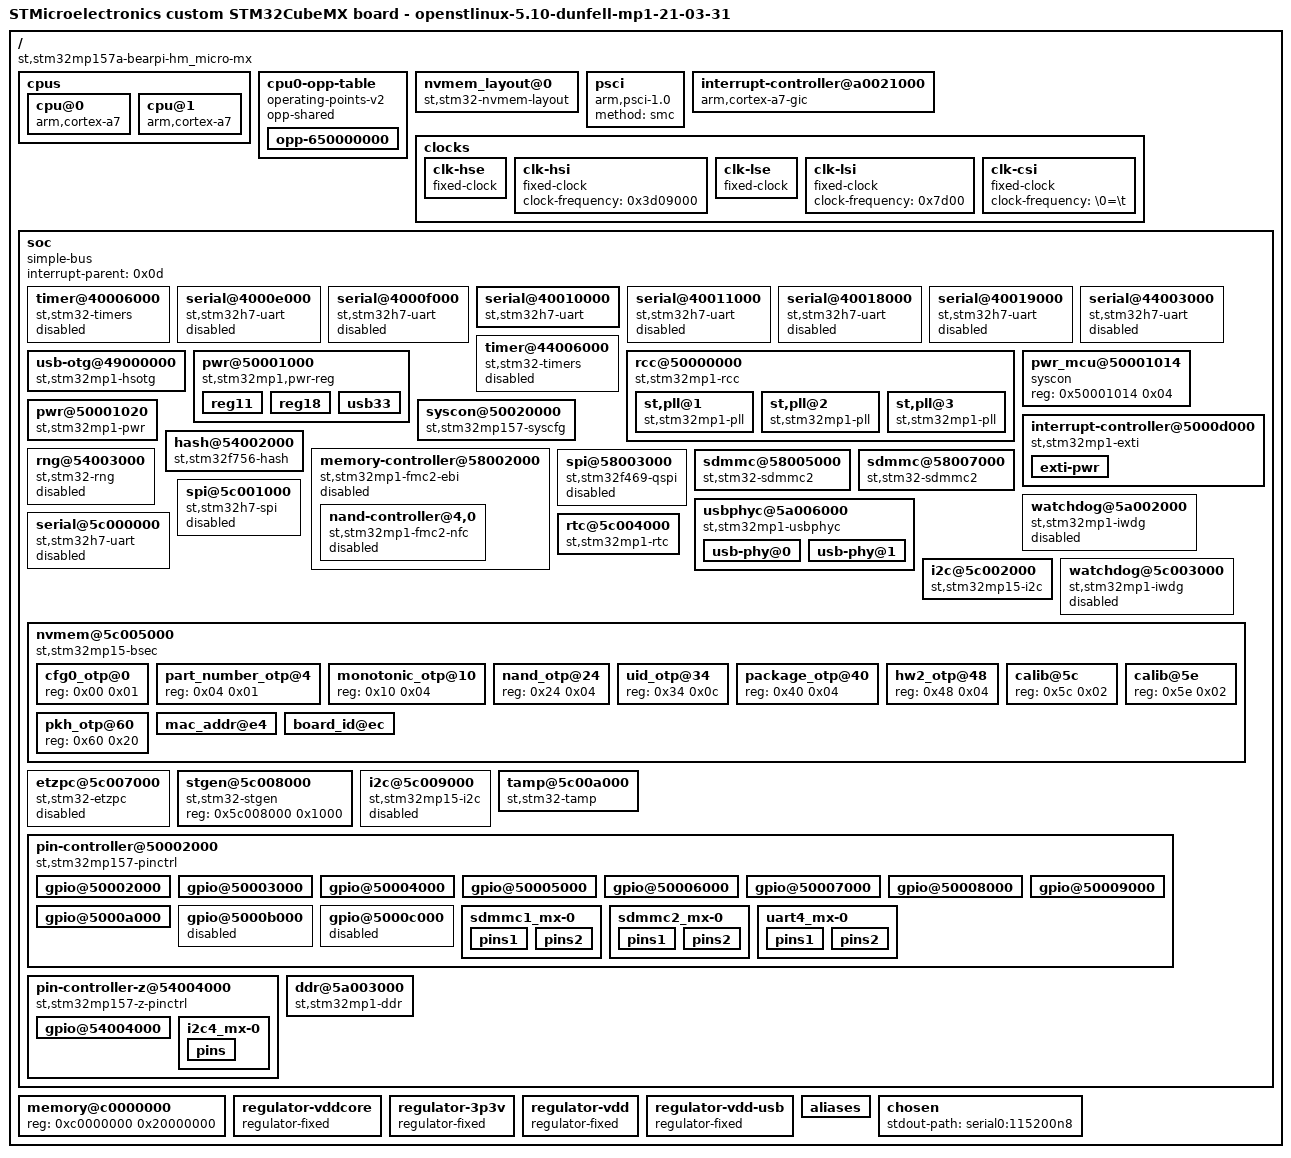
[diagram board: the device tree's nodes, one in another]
/dts-v1/;

/ {
	#address-cells = <0x01>;
	#size-cells = <0x01>;
	model = "STMicroelectronics custom STM32CubeMX board - openstlinux-5.10-dunfell-mp1-21-03-31";
	compatible = "st,stm32mp157a-bearpi-hm_micro-mx\0st,stm32mp157";

	cpus {
		#address-cells = <0x01>;
		#size-cells = <0x00>;

		cpu@0 {
			compatible = "arm,cortex-a7";
			device_type = "cpu";
			reg = <0x00>;
			clocks = <0x01 0xc2>;
			clock-names = "cpu";
			operating-points-v2 = <0x02>;
			nvmem-cells = <0x03>;
			nvmem-cell-names = "part_number";
			cpu-supply = <0x04>;
		};

		cpu@1 {
			compatible = "arm,cortex-a7";
			device_type = "cpu";
			reg = <0x01>;
			clocks = <0x01 0xc2>;
			clock-names = "cpu";
			operating-points-v2 = <0x02>;
			cpu-supply = <0x04>;
		};
	};

	cpu0-opp-table {
		compatible = "operating-points-v2";
		opp-shared;
		phandle = <0x02>;

		opp-650000000 {
			opp-hz = <0x00 0x26be3680>;
			opp-microvolt = <0x124f80>;
			opp-supported-hw = <0x01>;
		};
	};

	nvmem_layout@0 {
		compatible = "st,stm32-nvmem-layout";
		nvmem-cells = <0x05 0x03 0x06 0x07 0x08 0x09 0x0a 0x0b 0x0c>;
		nvmem-cell-names = "cfg0_otp\0part_number_otp\0monotonic_otp\0nand_otp\0uid_otp\0package_otp\0hw2_otp\0pkh_otp\0board_id";
	};

	psci {
		compatible = "arm,psci-1.0";
		method = "smc";
	};

	interrupt-controller@a0021000 {
		compatible = "arm,cortex-a7-gic";
		#interrupt-cells = <0x03>;
		interrupt-controller;
		reg = <0xa0021000 0x1000 0xa0022000 0x2000>;
		phandle = <0x0d>;
	};

	clocks {

		clk-hse {
			#clock-cells = <0x00>;
			compatible = "fixed-clock";
			clock-frequency = <0x16e3600>;
			st,digbypass;
		};

		clk-hsi {
			#clock-cells = <0x00>;
			compatible = "fixed-clock";
			clock-frequency = <0x3d09000>;
		};

		clk-lse {
			#clock-cells = <0x00>;
			compatible = "fixed-clock";
			clock-frequency = <0x8000>;
			st,drive = <0x02>;
		};

		clk-lsi {
			#clock-cells = <0x00>;
			compatible = "fixed-clock";
			clock-frequency = <0x7d00>;
		};

		clk-csi {
			#clock-cells = <0x00>;
			compatible = "fixed-clock";
			clock-frequency = "\0=\t";
		};
	};

	soc {
		compatible = "simple-bus";
		#address-cells = <0x01>;
		#size-cells = <0x01>;
		interrupt-parent = <0x0d>;
		ranges;

		timer@40006000 {
			#address-cells = <0x01>;
			#size-cells = <0x00>;
			compatible = "st,stm32-timers";
			reg = <0x40006000 0x400>;
			clocks = <0x01 0xcb>;
			clock-names = "int";
			status = "disabled";
			secure-status = "disabled";
		};

		serial@4000e000 {
			compatible = "st,stm32h7-uart";
			reg = <0x4000e000 0x400>;
			interrupts = <0x00 0x26 0x04>;
			clocks = <0x01 0x95>;
			resets = <0x01 0x4c0e>;
			status = "disabled";
		};

		serial@4000f000 {
			compatible = "st,stm32h7-uart";
			reg = <0x4000f000 0x400>;
			interrupts = <0x00 0x27 0x04>;
			clocks = <0x01 0x96>;
			resets = <0x01 0x4c0f>;
			status = "disabled";
		};

		serial@40010000 {
			compatible = "st,stm32h7-uart";
			reg = <0x40010000 0x400>;
			interrupts-extended = <0x0e 0x1e 0x04>;
			clocks = <0x01 0x97>;
			resets = <0x01 0x4c10>;
			wakeup-source;
			status = "okay";
			pinctrl-names = "default";
			pinctrl-0 = <0x0f>;
		};

		serial@40011000 {
			compatible = "st,stm32h7-uart";
			reg = <0x40011000 0x400>;
			interrupts = <0x00 0x35 0x04>;
			clocks = <0x01 0x98>;
			resets = <0x01 0x4c11>;
			status = "disabled";
		};

		serial@40018000 {
			compatible = "st,stm32h7-uart";
			reg = <0x40018000 0x400>;
			interrupts = <0x00 0x52 0x04>;
			clocks = <0x01 0x9a>;
			resets = <0x01 0x4c12>;
			status = "disabled";
		};

		serial@40019000 {
			compatible = "st,stm32h7-uart";
			reg = <0x40019000 0x400>;
			interrupts = <0x00 0x53 0x04>;
			clocks = <0x01 0x9b>;
			resets = <0x01 0x4c13>;
			status = "disabled";
		};

		serial@44003000 {
			compatible = "st,stm32h7-uart";
			reg = <0x44003000 0x400>;
			interrupts = <0x00 0x47 0x04>;
			clocks = <0x01 0x99>;
			resets = <0x01 0x4c4d>;
			status = "disabled";
		};

		timer@44006000 {
			#address-cells = <0x01>;
			#size-cells = <0x00>;
			compatible = "st,stm32-timers";
			reg = <0x44006000 0x400>;
			clocks = <0x01 0xd0>;
			clock-names = "int";
			status = "disabled";
			secure-status = "okay";
			st,hsi-cal-input = <0x07>;
			st,csi-cal-input = <0x08>;
		};

		usb-otg@49000000 {
			compatible = "st,stm32mp1-hsotg\0snps,dwc2";
			reg = <0x49000000 0x10000>;
			clocks = <0x01 0xa6>;
			clock-names = "otg";
			resets = <0x01 0x4cc8>;
			reset-names = "dwc2";
			interrupts = <0x00 0x62 0x04>;
			g-rx-fifo-size = <0x200>;
			g-np-tx-fifo-size = <0x20>;
			g-tx-fifo-size = <0x100 0x10 0x10 0x10 0x10 0x10 0x10 0x10>;
			dr_mode = "otg";
			usb33d-supply = <0x10>;
			status = "okay";
			phys = <0x11 0x00>;
			phy-names = "usb2-phy";
			usb-role-switch;
		};

		rcc@50000000 {
			compatible = "st,stm32mp1-rcc\0syscon";
			reg = <0x50000000 0x1000>;
			#address-cells = <0x01>;
			#size-cells = <0x00>;
			#clock-cells = <0x01>;
			#reset-cells = <0x01>;
			interrupts = <0x00 0x05 0x04>;
			secure-interrupts = <0x00 0x91 0x04>;
			secure-interrupt-names = "wakeup";
			st,csi-cal;
			st,hsi-cal;
			st,cal-sec = <0x3c>;
			st,clksrc = <0x202 0x242 0x483 0x281 0x8201 0x8241 0x1401 0x800f 0x804f>;
			st,clkdiv = <0x01 0x00 0x00 0x01 0x01 0x01 0x01 0x02 0x17 0x00 0x00>;
			st,pkcs = <0xd03 0x8fc3 0x8f42 0xd41 0x91c0 0x8d87 0x8dc7 0x8e07 0xc47 0xc00 0x8f87 0x800091c1 0x9283 0x9183 0x8c07 0x8c47 0xc87 0x8e82 0x8ec7 0x8e47 0x8f07 0x9143 0x8c87 0x8cc7 0x8d07 0x8d47 0x9347 0x9307 0x92c7>;
			status = "okay";
			secure-status = "okay";
			phandle = <0x01>;

			st,pll@1 {
				compatible = "st,stm32mp1-pll";
				reg = <0x01>;
				cfg = <0x02 0x41 0x01 0x01 0x00 0x05>;
				frac = <0x1400>;
			};

			st,pll@2 {
				compatible = "st,stm32mp1-pll";
				reg = <0x02>;
				cfg = <0x01 0x21 0x01 0x01 0x24 0x01>;
				frac = <0x1a04>;
			};

			st,pll@3 {
				compatible = "st,stm32mp1-pll";
				reg = <0x03>;
				cfg = <0x03 0x62 0x05 0x07 0x07 0x01>;
			};
		};

		pwr@50001000 {
			compatible = "st,stm32mp1,pwr-reg";
			reg = <0x50001000 0x10>;
			st,tzcr = <0x01 0x00 0x01>;
			status = "okay";
			secure-status = "okay";
			system_suspend_supported_soc_modes = <0x00 0x02 0x03 0x04>;
			system_off_soc_mode = <0x05>;
			vdd-supply = <0x12>;
			vdd_3v3_usbfs-supply = <0x13>;

			reg11 {
				regulator-name = "reg11";
				regulator-min-microvolt = <0x10c8e0>;
				regulator-max-microvolt = <0x10c8e0>;
				phandle = <0x18>;
			};

			reg18 {
				regulator-name = "reg18";
				regulator-min-microvolt = <0x1b7740>;
				regulator-max-microvolt = <0x1b7740>;
				phandle = <0x19>;
			};

			usb33 {
				regulator-name = "usb33";
				regulator-min-microvolt = <0x325aa0>;
				regulator-max-microvolt = <0x325aa0>;
				phandle = <0x10>;
			};
		};

		pwr_mcu@50001014 {
			compatible = "syscon";
			reg = <0x50001014 0x04>;
		};

		pwr@50001020 {
			compatible = "st,stm32mp1-pwr";
			reg = <0x50001020 0x100>;
			interrupts = <0x00 0x95 0x04>;
			interrupt-controller;
			#interrupt-cells = <0x03>;
			phandle = <0x14>;
		};

		interrupt-controller@5000d000 {
			compatible = "st,stm32mp1-exti\0syscon";
			interrupt-controller;
			#interrupt-cells = <0x02>;
			reg = <0x5000d000 0x400>;
			phandle = <0x0e>;

			exti-pwr {
				interrupt-controller;
				#interrupt-cells = <0x02>;
				interrupt-parent = <0x14>;
				st,irq-number = <0x06>;
			};
		};

		syscon@50020000 {
			compatible = "st,stm32mp157-syscfg\0syscon";
			reg = <0x50020000 0x400>;
			clocks = <0x01 0x33>;
			phandle = <0x1a>;
		};

		hash@54002000 {
			compatible = "st,stm32f756-hash";
			reg = <0x54002000 0x400>;
			interrupts = <0x00 0x50 0x04>;
			clocks = <0x01 0x61>;
			resets = <0x01 0xc85>;
			status = "okay";
			secure-status = "disabled";
		};

		rng@54003000 {
			compatible = "st,stm32-rng";
			reg = <0x54003000 0x400>;
			clocks = <0x01 0x7c>;
			resets = <0x01 0xc86>;
			status = "disabled";
			secure-status = "disabled";
		};

		memory-controller@58002000 {
			#address-cells = <0x02>;
			#size-cells = <0x01>;
			compatible = "st,stm32mp1-fmc2-ebi";
			reg = <0x58002000 0x1000>;
			clocks = <0x01 0x79>;
			resets = <0x01 0xccc>;
			status = "disabled";
			ranges = <0x00 0x00 0x60000000 0x4000000 0x01 0x00 0x64000000 0x4000000 0x02 0x00 0x68000000 0x4000000 0x03 0x00 0x6c000000 0x4000000 0x04 0x00 0x80000000 0x10000000>;

			nand-controller@4,0 {
				#address-cells = <0x01>;
				#size-cells = <0x00>;
				compatible = "st,stm32mp1-fmc2-nfc";
				reg = <0x04 0x00 0x1000 0x04 0x8010000 0x1000 0x04 0x8020000 0x1000 0x04 0x1000000 0x1000 0x04 0x9010000 0x1000 0x04 0x9020000 0x1000>;
				interrupts = <0x00 0x30 0x04>;
				status = "disabled";
			};
		};

		spi@58003000 {
			compatible = "st,stm32f469-qspi";
			reg = <0x58003000 0x1000 0x70000000 0x10000000>;
			reg-names = "qspi\0qspi_mm";
			interrupts = <0x00 0x5c 0x04>;
			clocks = <0x01 0x7a>;
			resets = <0x01 0xcce>;
			status = "disabled";
		};

		sdmmc@58005000 {
			compatible = "st,stm32-sdmmc2\0arm,pl18x\0arm,primecell";
			arm,primecell-periphid = <0x253180>;
			reg = <0x58005000 0x1000 0x58006000 0x1000>;
			interrupts = <0x00 0x31 0x04>;
			interrupt-names = "cmd_irq";
			clocks = <0x01 0x76>;
			clock-names = "apb_pclk";
			resets = <0x01 0xcd0>;
			cap-sd-highspeed;
			cap-mmc-highspeed;
			max-frequency = <0x7270e00>;
			status = "okay";
			pinctrl-names = "default";
			pinctrl-0 = <0x15>;
			disable-wp;
			st,neg-edge;
			bus-width = <0x04>;
			vmmc-supply = <0x16>;
		};

		sdmmc@58007000 {
			compatible = "st,stm32-sdmmc2\0arm,pl18x\0arm,primecell";
			arm,primecell-periphid = <0x253180>;
			reg = <0x58007000 0x1000 0x58008000 0x1000>;
			interrupts = <0x00 0x7c 0x04>;
			interrupt-names = "cmd_irq";
			clocks = <0x01 0x77>;
			clock-names = "apb_pclk";
			resets = <0x01 0xcd1>;
			cap-sd-highspeed;
			cap-mmc-highspeed;
			max-frequency = <0x7270e00>;
			status = "okay";
			pinctrl-names = "default";
			pinctrl-0 = <0x17>;
			non-removable;
			no-sd;
			no-sdio;
			st,neg-edge;
			bus-width = <0x08>;
			vmmc-supply = <0x16>;
			vqmmc-supply = <0x16>;
			mmc-ddr-3_3v;
		};

		watchdog@5a002000 {
			compatible = "st,stm32mp1-iwdg";
			reg = <0x5a002000 0x400>;
			secure-interrupts = <0x00 0x97 0x04>;
			clocks = <0x01 0x3a 0x01 0x02>;
			clock-names = "pclk\0lsi";
			status = "disabled";
			secure-status = "disabled";
		};

		usbphyc@5a006000 {
			#address-cells = <0x01>;
			#size-cells = <0x00>;
			#clock-cells = <0x00>;
			compatible = "st,stm32mp1-usbphyc";
			reg = <0x5a006000 0x1000>;
			clocks = <0x01 0x7f>;
			resets = <0x01 0xc10>;
			vdda1v1-supply = <0x18>;
			vdda1v8-supply = <0x19>;
			status = "okay";

			usb-phy@0 {
				#phy-cells = <0x00>;
				reg = <0x00>;
				status = "okay";
				phy-supply = <0x13>;
			};

			usb-phy@1 {
				#phy-cells = <0x01>;
				reg = <0x01>;
				status = "okay";
				phy-supply = <0x13>;
				phandle = <0x11>;
			};
		};

		serial@5c000000 {
			compatible = "st,stm32h7-uart";
			reg = <0x5c000000 0x400>;
			interrupts = <0x00 0x25 0x04>;
			clocks = <0x01 0x94>;
			resets = <0x01 0xc44>;
			status = "disabled";
			secure-status = "disabled";
		};

		spi@5c001000 {
			#address-cells = <0x01>;
			#size-cells = <0x00>;
			compatible = "st,stm32h7-spi";
			reg = <0x5c001000 0x400>;
			interrupts = <0x00 0x56 0x04>;
			clocks = <0x01 0x87>;
			resets = <0x01 0xc40>;
			status = "disabled";
			secure-status = "disabled";
		};

		i2c@5c002000 {
			compatible = "st,stm32mp15-i2c";
			reg = <0x5c002000 0x400>;
			interrupt-names = "event\0error";
			interrupts-extended = <0x0e 0x18 0x04 0x0d 0x00 0x60 0x04>;
			clocks = <0x01 0x8c>;
			resets = <0x01 0xc42>;
			#address-cells = <0x01>;
			#size-cells = <0x00>;
			st,syscfg-fmp = <0x1a 0x04 0x08>;
			wakeup-source;
			status = "okay";
			secure-status = "okay";
			pinctrl-names = "default";
			pinctrl-0 = <0x1b>;
			i2c-scl-rising-time-ns = <0xb9>;
			i2c-scl-falling-time-ns = <0x14>;
			clock-frequency = <0x61a80>;
		};

		watchdog@5c003000 {
			compatible = "st,stm32mp1-iwdg";
			reg = <0x5c003000 0x400>;
			interrupts = <0x00 0x96 0x04>;
			clocks = <0x01 0x44 0x01 0x02>;
			clock-names = "pclk\0lsi";
			status = "disabled";
			secure-status = "disabled";
		};

		rtc@5c004000 {
			compatible = "st,stm32mp1-rtc";
			reg = <0x5c004000 0x400>;
			clocks = <0x01 0x41 0x01 0xc0>;
			clock-names = "pclk\0rtc_ck";
			interrupts-extended = <0x0e 0x13 0x04>;
			status = "okay";
			secure-status = "okay";
		};

		nvmem@5c005000 {
			compatible = "st,stm32mp15-bsec";
			reg = <0x5c005000 0x400>;
			#address-cells = <0x01>;
			#size-cells = <0x01>;
			status = "okay";
			secure-status = "okay";

			cfg0_otp@0 {
				reg = <0x00 0x01>;
				phandle = <0x05>;
			};

			part_number_otp@4 {
				reg = <0x04 0x01>;
				phandle = <0x03>;
			};

			monotonic_otp@10 {
				reg = <0x10 0x04>;
				phandle = <0x06>;
			};

			nand_otp@24 {
				reg = <0x24 0x04>;
				phandle = <0x07>;
			};

			uid_otp@34 {
				reg = <0x34 0x0c>;
				phandle = <0x08>;
			};

			package_otp@40 {
				reg = <0x40 0x04>;
				phandle = <0x09>;
			};

			hw2_otp@48 {
				reg = <0x48 0x04>;
				phandle = <0x0a>;
			};

			calib@5c {
				reg = <0x5c 0x02>;
			};

			calib@5e {
				reg = <0x5e 0x02>;
			};

			pkh_otp@60 {
				reg = <0x60 0x20>;
				phandle = <0x0b>;
			};

			mac_addr@e4 {
				reg = <0xe4 0x08>;
				st,non-secure-otp;
			};

			board_id@ec {
				reg = <0xec 0x04>;
				st,non-secure-otp;
				phandle = <0x0c>;
			};
		};

		etzpc@5c007000 {
			compatible = "st,stm32-etzpc";
			reg = <0x5c007000 0x400>;
			clocks = <0x01 0x43>;
			status = "disabled";
			secure-status = "okay";
			st,decprot = <0x580300 0x590300 0x5a0300 0x80300 0x50300 0x200300 0x550300 0xa0101 0xb0101 0x00 0x10000>;
		};

		stgen@5c008000 {
			compatible = "st,stm32-stgen";
			reg = <0x5c008000 0x1000>;
		};

		i2c@5c009000 {
			compatible = "st,stm32mp15-i2c";
			reg = <0x5c009000 0x400>;
			interrupt-names = "event\0error";
			interrupts-extended = <0x0e 0x36 0x04 0x0d 0x00 0x88 0x04>;
			clocks = <0x01 0x8e>;
			resets = <0x01 0xc43>;
			#address-cells = <0x01>;
			#size-cells = <0x00>;
			st,syscfg-fmp = <0x1a 0x04 0x20>;
			wakeup-source;
			status = "disabled";
			secure-status = "disabled";
		};

		tamp@5c00a000 {
			compatible = "st,stm32-tamp\0simple-bus\0syscon\0simple-mfd";
			reg = <0x5c00a000 0x400>;
			secure-interrupts = <0x00 0xc5 0x04>;
			clocks = <0x01 0x41>;
			status = "okay";
			secure-status = "okay";
		};

		pin-controller@50002000 {
			#address-cells = <0x01>;
			#size-cells = <0x01>;
			compatible = "st,stm32mp157-pinctrl";
			ranges = <0x00 0x50002000 0xa400>;
			interrupt-parent = <0x0e>;
			st,syscfg = <0x0e 0x60 0xff>;
			pins-are-numbered;
			st,package = <0x04>;
			phandle = <0x1c>;

			gpio@50002000 {
				gpio-controller;
				#gpio-cells = <0x02>;
				interrupt-controller;
				#interrupt-cells = <0x02>;
				reg = <0x00 0x400>;
				clocks = <0x01 0x54>;
				st,bank-name = "GPIOA";
				status = "okay";
				ngpios = <0x10>;
				gpio-ranges = <0x1c 0x00 0x00 0x10>;
			};

			gpio@50003000 {
				gpio-controller;
				#gpio-cells = <0x02>;
				interrupt-controller;
				#interrupt-cells = <0x02>;
				reg = <0x1000 0x400>;
				clocks = <0x01 0x55>;
				st,bank-name = "GPIOB";
				status = "okay";
				ngpios = <0x10>;
				gpio-ranges = <0x1c 0x00 0x10 0x10>;
			};

			gpio@50004000 {
				gpio-controller;
				#gpio-cells = <0x02>;
				interrupt-controller;
				#interrupt-cells = <0x02>;
				reg = <0x2000 0x400>;
				clocks = <0x01 0x56>;
				st,bank-name = "GPIOC";
				status = "okay";
				ngpios = <0x10>;
				gpio-ranges = <0x1c 0x00 0x20 0x10>;
			};

			gpio@50005000 {
				gpio-controller;
				#gpio-cells = <0x02>;
				interrupt-controller;
				#interrupt-cells = <0x02>;
				reg = <0x3000 0x400>;
				clocks = <0x01 0x57>;
				st,bank-name = "GPIOD";
				status = "okay";
				ngpios = <0x10>;
				gpio-ranges = <0x1c 0x00 0x30 0x10>;
			};

			gpio@50006000 {
				gpio-controller;
				#gpio-cells = <0x02>;
				interrupt-controller;
				#interrupt-cells = <0x02>;
				reg = <0x4000 0x400>;
				clocks = <0x01 0x58>;
				st,bank-name = "GPIOE";
				status = "okay";
				ngpios = <0x10>;
				gpio-ranges = <0x1c 0x00 0x40 0x10>;
			};

			gpio@50007000 {
				gpio-controller;
				#gpio-cells = <0x02>;
				interrupt-controller;
				#interrupt-cells = <0x02>;
				reg = <0x5000 0x400>;
				clocks = <0x01 0x59>;
				st,bank-name = "GPIOF";
				status = "okay";
				ngpios = <0x10>;
				gpio-ranges = <0x1c 0x00 0x50 0x10>;
			};

			gpio@50008000 {
				gpio-controller;
				#gpio-cells = <0x02>;
				interrupt-controller;
				#interrupt-cells = <0x02>;
				reg = <0x6000 0x400>;
				clocks = <0x01 0x5a>;
				st,bank-name = "GPIOG";
				status = "okay";
				ngpios = <0x10>;
				gpio-ranges = <0x1c 0x00 0x60 0x10>;
			};

			gpio@50009000 {
				gpio-controller;
				#gpio-cells = <0x02>;
				interrupt-controller;
				#interrupt-cells = <0x02>;
				reg = <0x7000 0x400>;
				clocks = <0x01 0x5b>;
				st,bank-name = "GPIOH";
				status = "okay";
				ngpios = <0x10>;
				gpio-ranges = <0x1c 0x00 0x70 0x10>;
			};

			gpio@5000a000 {
				gpio-controller;
				#gpio-cells = <0x02>;
				interrupt-controller;
				#interrupt-cells = <0x02>;
				reg = <0x8000 0x400>;
				clocks = <0x01 0x5c>;
				st,bank-name = "GPIOI";
				status = "okay";
				ngpios = <0x0c>;
				gpio-ranges = <0x1c 0x00 0x80 0x0c>;
			};

			gpio@5000b000 {
				gpio-controller;
				#gpio-cells = <0x02>;
				interrupt-controller;
				#interrupt-cells = <0x02>;
				reg = <0x9000 0x400>;
				clocks = <0x01 0x5d>;
				st,bank-name = "GPIOJ";
				status = "disabled";
			};

			gpio@5000c000 {
				gpio-controller;
				#gpio-cells = <0x02>;
				interrupt-controller;
				#interrupt-cells = <0x02>;
				reg = <0xa000 0x400>;
				clocks = <0x01 0x5e>;
				st,bank-name = "GPIOK";
				status = "disabled";
			};

			sdmmc1_mx-0 {
				phandle = <0x15>;

				pins1 {
					pinmux = <0x280d 0x290d 0x2a0d 0x2b0d 0x320d>;
					bias-disable;
					drive-push-pull;
					slew-rate = <0x01>;
				};

				pins2 {
					pinmux = <0x2c0d>;
					bias-disable;
					drive-push-pull;
					slew-rate = <0x03>;
				};
			};

			sdmmc2_mx-0 {
				phandle = <0x17>;

				pins1 {
					pinmux = <0x80a 0x90b 0x130a 0x140a 0x1e0a 0x1f0a 0x330a 0x450a 0x660b>;
					bias-disable;
					drive-push-pull;
					slew-rate = <0x01>;
				};

				pins2 {
					pinmux = <0x430a>;
					bias-disable;
					drive-push-pull;
					slew-rate = <0x03>;
				};
			};

			uart4_mx-0 {
				phandle = <0x0f>;

				pins1 {
					pinmux = <0x1209>;
					bias-disable;
				};

				pins2 {
					pinmux = <0x6b07>;
					bias-disable;
					drive-push-pull;
					slew-rate = <0x00>;
				};
			};
		};

		pin-controller-z@54004000 {
			#address-cells = <0x01>;
			#size-cells = <0x01>;
			compatible = "st,stm32mp157-z-pinctrl";
			ranges = <0x00 0x54004000 0x400>;
			pins-are-numbered;
			interrupt-parent = <0x0e>;
			st,syscfg = <0x0e 0x60 0xff>;
			st,package = <0x04>;
			phandle = <0x1d>;

			gpio@54004000 {
				gpio-controller;
				#gpio-cells = <0x02>;
				interrupt-controller;
				#interrupt-cells = <0x02>;
				reg = <0x00 0x400>;
				clocks = <0x01 0x5f>;
				st,bank-name = "GPIOZ";
				st,bank-ioport = <0x0b>;
				status = "okay";
				secure-status = "okay";
				ngpios = <0x08>;
				gpio-ranges = <0x1d 0x00 0x190 0x08>;
			};

			i2c4_mx-0 {
				phandle = <0x1b>;

				pins {
					pinmux = <0x19407 0x19507>;
					bias-disable;
					drive-open-drain;
					slew-rate = <0x00>;
				};
			};
		};

		ddr@5a003000 {
			compatible = "st,stm32mp1-ddr";
			reg = <0x5a003000 0x550 0x5a004000 0x234>;
			clocks = <0x01 0xe4 0x01 0xdc 0x01 0xde 0x01 0xe0 0x01 0xe2 0x01 0xe5>;
			clock-names = "axidcg\0ddrc1\0ddrc2\0ddrphyc\0ddrcapb\0ddrphycapb";
			st,mem-name = "DDR3-DDR3L 16bits 533000Khz";
			st,mem-speed = <0x82208>;
			st,mem-size = <0x20000000>;
			st,ctl-reg = <0x41401 0x10 0x00 0x00 0x800000 0x00 0x400010 0x00 0x210000 0x00 0x00 0xc2000040 0x2060105 0x202 0x7000000 0xc0400003 0x00 0x00 0x00 0x01 0x00 0x00 0x00 0x00 0x10>;
			st,ctl-timing = <0x81008b 0x121b2414 0xa041c 0x608090f 0x50400c 0x8040608 0x6060403 0x2020002 0x202 0x1005 0xa0 0x6000600>;
			st,ctl-map = <0x70707 0x00 0x1f000000 0x1f1f 0x6060606 0xf060606 0x00 0x00 0x00>;
			st,ctl-perf = <0xc01 0x00 0x1000001 0x8000200 0x8000400 0x10000 0x00 0x2100c03 0x800100 0x1100c03 0x1000200 0x10000 0x00 0x2100c03 0x800040 0x1100c03 0x1000200>;
			st,phy-reg = <0x1442e02 0x10400812 0xc40 0xf200011f 0x0b 0x10000 0x38 0xce81 0xce81 0xce80 0xce80>;
			st,phy-timing = <0x22aa5b 0x4841104 0x42da068 0x38d488d0 0x98b00d8 0x10023600 0x840 0x00 0x208 0x00>;
			status = "okay";
		};
	};

	memory@c0000000 {
		device_type = "memory";
		reg = <0xc0000000 0x20000000>;
	};

	regulator-vddcore {
		compatible = "regulator-fixed";
		regulator-name = "vddcore";
		regulator-min-microvolt = <0x124f80>;
		regulator-max-microvolt = <0x149970>;
		regulator-off-in-suspend;
		regulator-always-on;
		phandle = <0x04>;
	};

	regulator-3p3v {
		compatible = "regulator-fixed";
		regulator-name = "v3v3";
		regulator-min-microvolt = <0x325aa0>;
		regulator-max-microvolt = <0x325aa0>;
		regulator-off-in-suspend;
		regulator-always-on;
		phandle = <0x16>;
	};

	regulator-vdd {
		compatible = "regulator-fixed";
		regulator-name = "vdd";
		regulator-min-microvolt = <0x325aa0>;
		regulator-max-microvolt = <0x325aa0>;
		regulator-off-in-suspend;
		regulator-always-on;
		phandle = <0x12>;
	};

	regulator-vdd-usb {
		compatible = "regulator-fixed";
		regulator-name = "vdd_usb";
		regulator-min-microvolt = <0x325aa0>;
		regulator-max-microvolt = <0x325aa0>;
		regulator-off-in-suspend;
		regulator-always-on;
		phandle = <0x13>;
	};

	aliases {
		serial0 = "/soc/serial@40010000";
		serial1 = "/soc/serial@4000f000";
		serial2 = "/soc/serial@40018000";
	};

	chosen {
		stdout-path = "serial0:115200n8";
	};
};
